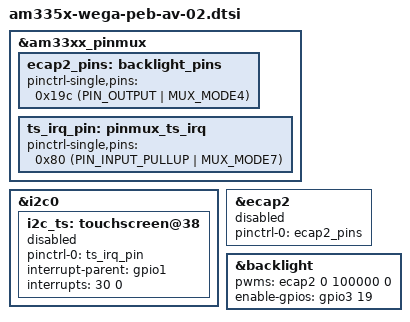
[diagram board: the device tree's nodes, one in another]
/*
 * Copyright (C) 2014 Christian Arlt <c.arlt@phytec.de> Phytec Messtechnik GmbH
 *
 * This program is free software; you can redistribute it and/or modify
 * it under the terms of the GNU General Public License version 2 as
 * published by the Free Software Foundation.
 */

&am33xx_pinmux {
	ecap2_pins: backlight_pins {
		pinctrl-single,pins = <
			0x19c (PIN_OUTPUT | MUX_MODE4)		/* mcasp0_ahclkr.ecap2_in_pwm2_out	*/
		>;
	};

	ts_irq_pin: pinmux_ts_irq {
		pinctrl-single,pins = <
			0x80 (PIN_INPUT_PULLUP | MUX_MODE7)	/* gpmc_csn1.x_av_int_gpio1_30	*/
		>;
	};
};

&i2c0 {
	i2c_ts: touchscreen@38 {
		pinctrl-names = "default";
		pinctrl-0 = <&ts_irq_pin>;
		interrupt-parent = <&gpio1>;
		interrupts = <30 0>;
		status = "disabled";
	};
};

&ecap2 {
	pinctrl-names = "default";
	pinctrl-0 = <&ecap2_pins>;
	status = "disabled";
};

#include "am335x-phytec-lcd-018.dtsi"

&backlight {
	pwms = <&ecap2 0 100000 0>;
	enable-gpios = <&gpio3 19 0>;
};
